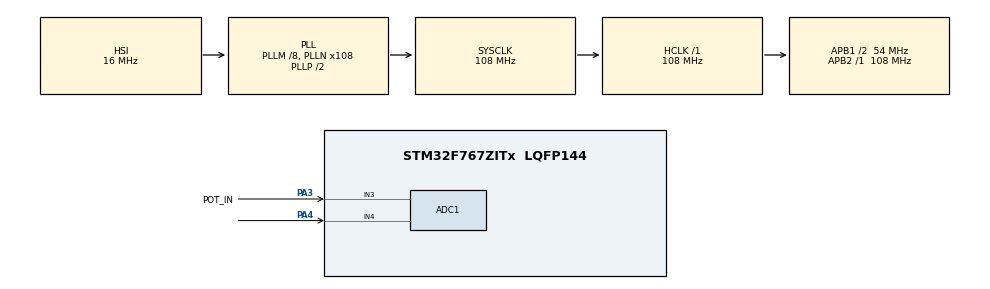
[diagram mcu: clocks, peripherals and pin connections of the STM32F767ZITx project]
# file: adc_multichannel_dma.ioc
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ADC1.Channel-0\#ChannelRegularConversion=ADC_CHANNEL_3
ADC1.Channel-1\#ChannelRegularConversion=ADC_CHANNEL_4
ADC1.ContinuousConvMode=ENABLE
ADC1.DMAContinuousRequests=ENABLE
ADC1.DiscontinuousConvMode=DISABLE
ADC1.EOCSelection=ADC_EOC_SEQ_CONV
ADC1.NbrOfConversion=2
ADC1.NbrOfConversionFlag=1
ADC1.Rank-0\#ChannelRegularConversion=1
ADC1.Rank-1\#ChannelRegularConversion=2
ADC1.SamplingTime-0\#ChannelRegularConversion=ADC_SAMPLETIME_480CYCLES
ADC1.SamplingTime-1\#ChannelRegularConversion=ADC_SAMPLETIME_480CYCLES
ADC1.ScanConvMode=ADC_SCAN_ENABLE
ADC1.master=1
Dma.ADC1.0.Direction=DMA_PERIPH_TO_MEMORY
Dma.ADC1.0.FIFOMode=DMA_FIFOMODE_DISABLE
Dma.ADC1.0.Instance=DMA2_Stream0
Dma.ADC1.0.MemDataAlignment=DMA_MDATAALIGN_HALFWORD
Dma.ADC1.0.MemInc=DMA_MINC_ENABLE
Dma.ADC1.0.Mode=DMA_CIRCULAR
Dma.ADC1.0.PeriphDataAlignment=DMA_PDATAALIGN_HALFWORD
Dma.ADC1.0.PeriphInc=DMA_PINC_DISABLE
Dma.ADC1.0.Priority=DMA_PRIORITY_LOW
Dma.Request0=ADC1
Mcu.Family=STM32F7
Mcu.Name=STM32F767ZITx
Mcu.Package=LQFP144
NVIC.ADC_IRQn=true\:1\:0\:true\:false\:true\:true\:true\:true
NVIC.DMA2_Stream0_IRQn=true\:0\:0\:false\:false\:true\:false\:true\:true
NVIC.PriorityGroup=NVIC_PRIORITYGROUP_4
PA3.GPIO_Label=POT_IN
PA3.Signal=ADCx_IN3
PA4.Signal=ADCx_IN4
PH0/OSC_IN.Mode=HSE-External-Oscillator
PH0/OSC_IN.Signal=RCC_OSC_IN
PH1/OSC_OUT.Mode=HSE-External-Oscillator
PH1/OSC_OUT.Signal=RCC_OSC_OUT
ProjectManager.HeapSize=0x200
ProjectManager.StackSize=0x400
ProjectManager.TargetToolchain=STM32CubeIDE
RCC.48MHZClocksFreq_Value=24000000
RCC.AHBFreq_Value=108000000
RCC.APB1CLKDivider=RCC_HCLK_DIV2
RCC.APB1Freq_Value=54000000
RCC.APB1TimFreq_Value=108000000
RCC.APB2Freq_Value=108000000
RCC.APB2TimFreq_Value=108000000
RCC.CortexFreq_Value=108000000
RCC.HCLKFreq_Value=108000000
RCC.HSE_VALUE=8000000
RCC.HSI_VALUE=16000000
RCC.LSE_VALUE=32768
RCC.PLLM=8
RCC.PLLMUL=RCC_PLL_MUL9
RCC.PLLN=108
RCC.PRESCALERUSB=RCC_USBCLKSOURCE_PLL_DIV1_5
RCC.SYSCLKFreq_VALUE=108000000
RCC.SYSCLKSource=RCC_SYSCLKSOURCE_PLLCLK
RCC.SYSCLKSourceVirtual=RCC_SYSCLKSOURCE_PLLCLK
RCC.USBFreq_Value=108000000
RCC.VCOOutputFreq_Value=216000000
SH.ADCx_IN3.0=ADC1_IN3,IN3
SH.ADCx_IN4.0=ADC1_IN4,IN4
board=NUCLEO-F767ZI

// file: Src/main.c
/* USER CODE BEGIN Header */
/**
  ******************************************************************************
  * @file           : main.c
  * @brief          : Main program body
  ******************************************************************************
  * @attention
  *
  * Copyright (c) 2025 STMicroelectronics.
  * All rights reserved.
  *
  * This software is licensed under terms that can be found in the LICENSE file
  * in the root directory of this software component.
  * If no LICENSE file comes with this software, it is provided AS-IS.
  *
  ******************************************************************************
  */
/* USER CODE END Header */
#include "main.h"

/* USER CODE BEGIN Includes */
# include <stdbool.h>
/* USER CODE END Includes */

ADC_HandleTypeDef hadc1;
DMA_HandleTypeDef hdma_adc1;

void SystemClock_Config(void);
static void MX_GPIO_Init(void);
static void MX_DMA_Init(void);
static void MX_ADC1_Init(void);

/* USER CODE BEGIN 0 */
float pot_adc_volt = 0;
float ldr_adc_volt = 0;
volatile uint16_t pot_adc_val = 0;
volatile uint16_t ldr_adc_val = 0;
volatile uint16_t raw_adc_vals[2];
volatile bool conv_completed = false;
uint16_t count = 0;

/* USER CODE END 0 */

int main(void)
{

  /* MCU Configuration--------------------------------------------------------*/

  /* Reset of all peripherals, Initializes the Flash interface and the Systick. */
  HAL_Init();

  /* Configure the system clock */
  SystemClock_Config();

  /* Initialize all configured peripherals */
  MX_GPIO_Init();
  MX_DMA_Init();
  MX_ADC1_Init();
  /* USER CODE BEGIN 2 */
  HAL_ADC_Start_DMA(&hadc1, (uint32_t*)raw_adc_vals, 2);

  /* USER CODE END 2 */

  /* Infinite loop */
  while (1)
  {

    /* USER CODE BEGIN 3 */

    count++;
    if(conv_completed){
      // Do whatever calculations/actions you want to do with the ADC readings
      pot_adc_volt = (float)pot_adc_val * (3.3f / 4095.0f);
      ldr_adc_volt = (float)ldr_adc_val * (3.3f / 4095.0f);
      conv_completed = false;
    }
    HAL_Delay(5);
  }
  /* USER CODE END 3 */
}

void SystemClock_Config(void)
{
  RCC_OscInitTypeDef RCC_OscInitStruct = {0};
  RCC_ClkInitTypeDef RCC_ClkInitStruct = {0};

  /** Configure the main internal regulator output voltage
  */
  __HAL_RCC_PWR_CLK_ENABLE();
  __HAL_PWR_VOLTAGESCALING_CONFIG(PWR_REGULATOR_VOLTAGE_SCALE3);

  /** Initializes the RCC Oscillators according to the specified parameters
  * in the RCC_OscInitTypeDef structure.
  */
  RCC_OscInitStruct.OscillatorType = RCC_OSCILLATORTYPE_HSI;
  RCC_OscInitStruct.HSIState = RCC_HSI_ON;
  RCC_OscInitStruct.HSICalibrationValue = RCC_HSICALIBRATION_DEFAULT;
  RCC_OscInitStruct.PLL.PLLState = RCC_PLL_ON;
  RCC_OscInitStruct.PLL.PLLSource = RCC_PLLSOURCE_HSI;
  RCC_OscInitStruct.PLL.PLLM = 8;
  RCC_OscInitStruct.PLL.PLLN = 108;
  RCC_OscInitStruct.PLL.PLLP = RCC_PLLP_DIV2;
  RCC_OscInitStruct.PLL.PLLQ = 2;
  RCC_OscInitStruct.PLL.PLLR = 2;
  if (HAL_RCC_OscConfig(&RCC_OscInitStruct) != HAL_OK)
  {
    Error_Handler();
  }

  /** Activate the Over-Drive mode
  */
  if (HAL_PWREx_EnableOverDrive() != HAL_OK)
  {
    Error_Handler();
  }

  /** Initializes the CPU, AHB and APB buses clocks
  */
  RCC_ClkInitStruct.ClockType = RCC_CLOCKTYPE_HCLK|RCC_CLOCKTYPE_SYSCLK
                              |RCC_CLOCKTYPE_PCLK1|RCC_CLOCKTYPE_PCLK2;
  RCC_ClkInitStruct.SYSCLKSource = RCC_SYSCLKSOURCE_PLLCLK;
  RCC_ClkInitStruct.AHBCLKDivider = RCC_SYSCLK_DIV1;
  RCC_ClkInitStruct.APB1CLKDivider = RCC_HCLK_DIV2;
  RCC_ClkInitStruct.APB2CLKDivider = RCC_HCLK_DIV1;

  if (HAL_RCC_ClockConfig(&RCC_ClkInitStruct, FLASH_LATENCY_3) != HAL_OK)
  {
    Error_Handler();
  }
}

static void MX_ADC1_Init(void)
{

  ADC_ChannelConfTypeDef sConfig = {0};

  /** Configure the global features of the ADC (Clock, Resolution, Data Alignment and number of conversion)
  */
  hadc1.Instance = ADC1;
  hadc1.Init.ClockPrescaler = ADC_CLOCK_SYNC_PCLK_DIV4;
  hadc1.Init.Resolution = ADC_RESOLUTION_12B;
  hadc1.Init.ScanConvMode = ADC_SCAN_ENABLE;
  hadc1.Init.ContinuousConvMode = ENABLE;
  hadc1.Init.DiscontinuousConvMode = DISABLE;
  hadc1.Init.ExternalTrigConvEdge = ADC_EXTERNALTRIGCONVEDGE_NONE;
  hadc1.Init.ExternalTrigConv = ADC_SOFTWARE_START;
  hadc1.Init.DataAlign = ADC_DATAALIGN_RIGHT;
  hadc1.Init.NbrOfConversion = 2;
  hadc1.Init.DMAContinuousRequests = ENABLE;
  hadc1.Init.EOCSelection = ADC_EOC_SEQ_CONV;
  if (HAL_ADC_Init(&hadc1) != HAL_OK)
  {
    Error_Handler();
  }

  /** Configure for the selected ADC regular channel its corresponding rank in the sequencer and its sample time.
  */
  sConfig.Channel = ADC_CHANNEL_3;
  sConfig.Rank = ADC_REGULAR_RANK_1;
  sConfig.SamplingTime = ADC_SAMPLETIME_480CYCLES;
  if (HAL_ADC_ConfigChannel(&hadc1, &sConfig) != HAL_OK)
  {
    Error_Handler();
  }

  /** Configure for the selected ADC regular channel its corresponding rank in the sequencer and its sample time.
  */
  sConfig.Channel = ADC_CHANNEL_4;
  sConfig.Rank = ADC_REGULAR_RANK_2;
  if (HAL_ADC_ConfigChannel(&hadc1, &sConfig) != HAL_OK)
  {
    Error_Handler();
  }

}

static void MX_DMA_Init(void)
{

  /* DMA controller clock enable */
  __HAL_RCC_DMA2_CLK_ENABLE();

  /* DMA interrupt init */
  /* DMA2_Stream0_IRQn interrupt configuration */
  HAL_NVIC_SetPriority(DMA2_Stream0_IRQn, 0, 0);
  HAL_NVIC_EnableIRQ(DMA2_Stream0_IRQn);

}

static void MX_GPIO_Init(void)
{

  /* GPIO Ports Clock Enable */
  __HAL_RCC_GPIOH_CLK_ENABLE();
  __HAL_RCC_GPIOA_CLK_ENABLE();

}

/* USER CODE BEGIN 4 */
void HAL_ADC_ConvCpltCallback(ADC_HandleTypeDef* hadc){
  ldr_adc_val = raw_adc_vals[0];
  pot_adc_val = raw_adc_vals[1];
  conv_completed = true;
  // __NOP(); // Only for debugging to check if the callback is triggered correctly. It is like "pass" keyword in Python.
}

/* USER CODE END 4 */

void Error_Handler(void)
{
  __disable_irq();
  while (1)
  {
  }
}
